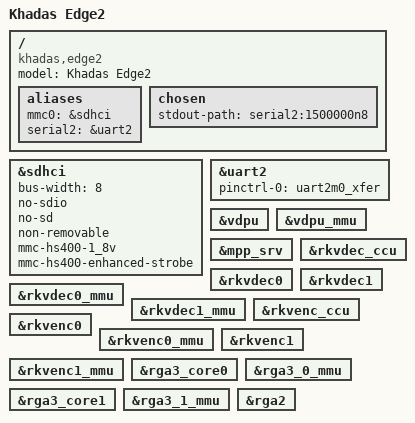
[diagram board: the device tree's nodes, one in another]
// SPDX-License-Identifier: (GPL-2.0+ OR MIT)

/dts-v1/;

#include <dt-bindings/gpio/gpio.h>
#include <dt-bindings/pinctrl/rockchip.h>
#include "rk3588s.dtsi"
#include "rk3588-mpp.dtsi"
#include "rk3588-rga-multi.dtsi"

/ {
	model = "Khadas Edge2";
	compatible = "khadas,edge2", "rockchip,rk3588s";

	aliases {
		mmc0 = &sdhci;
		serial2 = &uart2;
	};

	chosen {
		stdout-path = "serial2:1500000n8";
	};
};

&sdhci {
	bus-width = <8>;
	no-sdio;
	no-sd;
	non-removable;
	mmc-hs400-1_8v;
	mmc-hs400-enhanced-strobe;
	status = "okay";
};

&uart2 {
	pinctrl-0 = <&uart2m0_xfer>;
	status = "okay";
};

&vdpu {
    status = "okay";
};

&vdpu_mmu {
    status = "okay";
};

&mpp_srv {
    status = "okay";
};

&rkvdec_ccu {
    status = "okay";
};

&rkvdec0 {
    status = "okay";
};

&rkvdec0_mmu {
    status = "okay";
};

&rkvdec1 {
    status = "okay";
};

&rkvdec1_mmu {
    status = "okay";
};

&rkvenc_ccu {
    status = "okay";
};

&rkvenc0 {
    status = "okay";
};

&rkvenc0_mmu {
    status = "okay";
};

&rkvenc1 {
    status = "okay";
};

&rkvenc1_mmu {
    status = "okay";
};

&rga3_core0 {
    status = "okay";
};

&rga3_0_mmu {
    status = "okay";
};

&rga3_core1 {
    status = "okay";
};

&rga3_1_mmu {
    status = "okay";
};

&rga2 {
    status = "okay";
};
